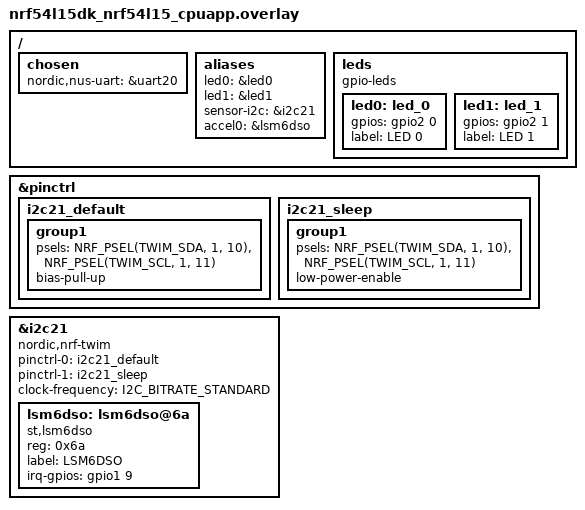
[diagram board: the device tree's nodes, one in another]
/*
 * Copyright (c) 2024 Nordic Semiconductor ASA
 *
 * SPDX-License-Identifier: LicenseRef-Nordic-5-Clause
 */

/ {
	chosen {
		nordic,nus-uart = &uart20;
	};

	aliases {
		led0 = &led0;
		led1 = &led1;
		sensor-i2c = &i2c21;
		accel0 = &lsm6dso;
	};

	leds {
		compatible = "gpio-leds";
		led0: led_0 {
			gpios = <&gpio2 0 GPIO_ACTIVE_HIGH>;
			label = "LED 0";
		};
		led1: led_1 {
			gpios = <&gpio2 1 GPIO_ACTIVE_HIGH>;
			label = "LED 1";
		};
	};
};

&pinctrl {
	/omit-if-no-ref/ i2c21_default: i2c21_default {
		group1 {
			psels = <NRF_PSEL(TWIM_SDA, 1, 10)>,
				<NRF_PSEL(TWIM_SCL, 1, 11)>;
			bias-pull-up;
		};
	};

	/omit-if-no-ref/ i2c21_sleep: i2c21_sleep {
		group1 {
			psels = <NRF_PSEL(TWIM_SDA, 1, 10)>,
				<NRF_PSEL(TWIM_SCL, 1, 11)>;
			low-power-enable;
		};
	};
};

&i2c21 {
	compatible = "nordic,nrf-twim";
	status = "okay";
	pinctrl-0 = <&i2c21_default>;
	pinctrl-1 = <&i2c21_sleep>;
	pinctrl-names = "default", "sleep";
	clock-frequency = <I2C_BITRATE_STANDARD>;

	lsm6dso: lsm6dso@6a {
		compatible = "st,lsm6dso";
		reg = <0x6a>;
		label = "LSM6DSO";
		irq-gpios = <&gpio1 9 GPIO_ACTIVE_HIGH>;
	};
};
